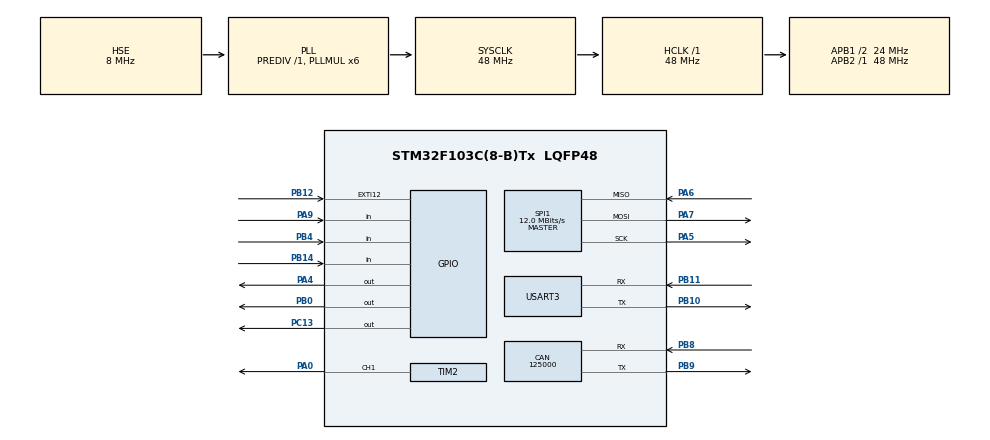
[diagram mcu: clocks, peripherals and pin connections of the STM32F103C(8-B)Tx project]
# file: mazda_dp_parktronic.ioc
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CAN.BS1=CAN_BS1_9TQ
CAN.BS2=CAN_BS2_2TQ
CAN.CalculateBaudRate=125000
CAN.CalculateTimeBit=7999.99
CAN.CalculateTimeQuantum=666.6666666666666
Mcu.Family=STM32F1
Mcu.Name=STM32F103C(8-B)Tx
Mcu.Package=LQFP48
NVIC.EXTI15_10_IRQn=true\:0\:0\:false\:false\:true\:true\:true
NVIC.PriorityGroup=NVIC_PRIORITYGROUP_4
PA0-WKUP.Signal=S_TIM2_CH1_ETR
PA13.Mode=Serial_Wire
PA13.Signal=SYS_JTMS-SWDIO
PA14.Mode=Serial_Wire
PA14.Signal=SYS_JTCK-SWCLK
PA4.Signal=GPIO_Output
PA5.Mode=Full_Duplex_Master
PA5.Signal=SPI1_SCK
PA6.Mode=Full_Duplex_Master
PA6.Signal=SPI1_MISO
PA7.Mode=Full_Duplex_Master
PA7.Signal=SPI1_MOSI
PA9.Signal=GPIO_Input
PB0.Signal=GPIO_Output
PB10.Mode=Asynchronous
PB10.Signal=USART3_TX
PB11.Mode=Asynchronous
PB11.Signal=USART3_RX
PB12.GPIO_ModeDefaultEXTI=GPIO_MODE_IT_RISING_FALLING
PB12.Signal=GPXTI12
PB14.Signal=GPIO_Input
PB4.Signal=GPIO_Input
PB8.Mode=CAN_Activate
PB8.Signal=CAN_RX
PB9.Mode=CAN_Activate
PB9.Signal=CAN_TX
PC13-TAMPER-RTC.Signal=GPIO_Output
PD0-OSC_IN.Mode=HSE-External-Oscillator
PD0-OSC_IN.Signal=RCC_OSC_IN
PD1-OSC_OUT.Mode=HSE-External-Oscillator
PD1-OSC_OUT.Signal=RCC_OSC_OUT
ProjectManager.HeapSize=0x200
ProjectManager.StackSize=0x400
ProjectManager.TargetToolchain=Makefile
RCC.AHBFreq_Value=48000000
RCC.APB1CLKDivider=RCC_HCLK_DIV2
RCC.APB1Freq_Value=24000000
RCC.APB1TimFreq_Value=48000000
RCC.APB2Freq_Value=48000000
RCC.APB2TimFreq_Value=48000000
RCC.HCLKFreq_Value=48000000
RCC.PLLMUL=RCC_PLL_MUL6
RCC.PLLSourceVirtual=RCC_PLLSOURCE_HSE
RCC.SYSCLKFreq_VALUE=48000000
RCC.SYSCLKSource=RCC_SYSCLKSOURCE_PLLCLK
RCC.USBFreq_Value=48000000
SH.S_TIM2_CH1_ETR.0=TIM2_CH1,Output Compare1 CH1
SPI1.BaudRatePrescaler=SPI_BAUDRATEPRESCALER_4
SPI1.CalculateBaudRate=12.0 MBits/s
SPI1.Direction=SPI_DIRECTION_2LINES
SPI1.Mode=SPI_MODE_MASTER
SPI1.VirtualType=VM_MASTER
TIM2.Channel-Output\ Compare1\ CH1=TIM_CHANNEL_1
USART3.VirtualMode=VM_ASYNC
board=custom

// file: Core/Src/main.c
/* USER CODE BEGIN Header */
/**
  ******************************************************************************
  * @file           : main.c
  * @brief          : Main program body
  ******************************************************************************
  * @attention
  *
  * <h2><center>&copy; Copyright (c) 2021 STMicroelectronics.
  * All rights reserved.</center></h2>
  *
  * This software component is licensed by ST under BSD 3-Clause license,
  * the "License"; You may not use this file except in compliance with the
  * License. You may obtain a copy of the License at:
  *                        opensource.org/licenses/BSD-3-Clause
  *
  ******************************************************************************
  */
/* USER CODE END Header */
#include "main.h"

/* USER CODE BEGIN Includes */
#include "mdp.h"
/* USER CODE END Includes */

CAN_HandleTypeDef hcan;

SPI_HandleTypeDef hspi1;

TIM_HandleTypeDef htim2;

UART_HandleTypeDef huart3;

void SystemClock_Config(void);
static void MX_GPIO_Init(void);
static void MX_USART3_UART_Init(void);
static void MX_CAN_Init(void);
static void MX_SPI1_Init(void);
static void MX_TIM2_Init(void);

int main(void)
{

  /* MCU Configuration--------------------------------------------------------*/

  /* Reset of all peripherals, Initializes the Flash interface and the Systick. */
  HAL_Init();

  /* Configure the system clock */
  SystemClock_Config();

  /* Initialize all configured peripherals */
  MX_GPIO_Init();
  MX_USART3_UART_Init();
  MX_CAN_Init();
  MX_SPI1_Init();
  MX_TIM2_Init();
  /* USER CODE BEGIN 2 */
  mdp_init();
  /* USER CODE END 2 */

  /* Infinite loop */
  while (1)
  {

    /* USER CODE BEGIN 3 */
    mdp_run();
  }
  /* USER CODE END 3 */
}

void SystemClock_Config(void)
{
  RCC_OscInitTypeDef RCC_OscInitStruct = {0};
  RCC_ClkInitTypeDef RCC_ClkInitStruct = {0};

  /** Initializes the RCC Oscillators according to the specified parameters
  * in the RCC_OscInitTypeDef structure.
  */
  RCC_OscInitStruct.OscillatorType = RCC_OSCILLATORTYPE_HSE;
  RCC_OscInitStruct.HSEState = RCC_HSE_ON;
  RCC_OscInitStruct.HSEPredivValue = RCC_HSE_PREDIV_DIV1;
  RCC_OscInitStruct.HSIState = RCC_HSI_ON;
  RCC_OscInitStruct.PLL.PLLState = RCC_PLL_ON;
  RCC_OscInitStruct.PLL.PLLSource = RCC_PLLSOURCE_HSE;
  RCC_OscInitStruct.PLL.PLLMUL = RCC_PLL_MUL6;
  if (HAL_RCC_OscConfig(&RCC_OscInitStruct) != HAL_OK)
  {
    Error_Handler();
  }
  /** Initializes the CPU, AHB and APB buses clocks
  */
  RCC_ClkInitStruct.ClockType = RCC_CLOCKTYPE_HCLK|RCC_CLOCKTYPE_SYSCLK
                              |RCC_CLOCKTYPE_PCLK1|RCC_CLOCKTYPE_PCLK2;
  RCC_ClkInitStruct.SYSCLKSource = RCC_SYSCLKSOURCE_PLLCLK;
  RCC_ClkInitStruct.AHBCLKDivider = RCC_SYSCLK_DIV1;
  RCC_ClkInitStruct.APB1CLKDivider = RCC_HCLK_DIV2;
  RCC_ClkInitStruct.APB2CLKDivider = RCC_HCLK_DIV1;

  if (HAL_RCC_ClockConfig(&RCC_ClkInitStruct, FLASH_LATENCY_1) != HAL_OK)
  {
    Error_Handler();
  }
}

static void MX_CAN_Init(void)
{

  hcan.Instance = CAN1;
  hcan.Init.Prescaler = 16;
  hcan.Init.Mode = CAN_MODE_NORMAL;
  hcan.Init.SyncJumpWidth = CAN_SJW_1TQ;
  hcan.Init.TimeSeg1 = CAN_BS1_9TQ;
  hcan.Init.TimeSeg2 = CAN_BS2_2TQ;
  hcan.Init.TimeTriggeredMode = DISABLE;
  hcan.Init.AutoBusOff = DISABLE;
  hcan.Init.AutoWakeUp = DISABLE;
  hcan.Init.AutoRetransmission = DISABLE;
  hcan.Init.ReceiveFifoLocked = DISABLE;
  hcan.Init.TransmitFifoPriority = DISABLE;
  if (HAL_CAN_Init(&hcan) != HAL_OK)
  {
    Error_Handler();
  }

}

static void MX_SPI1_Init(void)
{

  /* SPI1 parameter configuration*/
  hspi1.Instance = SPI1;
  hspi1.Init.Mode = SPI_MODE_MASTER;
  hspi1.Init.Direction = SPI_DIRECTION_2LINES;
  hspi1.Init.DataSize = SPI_DATASIZE_8BIT;
  hspi1.Init.CLKPolarity = SPI_POLARITY_LOW;
  hspi1.Init.CLKPhase = SPI_PHASE_1EDGE;
  hspi1.Init.NSS = SPI_NSS_SOFT;
  hspi1.Init.BaudRatePrescaler = SPI_BAUDRATEPRESCALER_4;
  hspi1.Init.FirstBit = SPI_FIRSTBIT_MSB;
  hspi1.Init.TIMode = SPI_TIMODE_DISABLE;
  hspi1.Init.CRCCalculation = SPI_CRCCALCULATION_DISABLE;
  hspi1.Init.CRCPolynomial = 10;
  if (HAL_SPI_Init(&hspi1) != HAL_OK)
  {
    Error_Handler();
  }

}

static void MX_TIM2_Init(void)
{

  TIM_MasterConfigTypeDef sMasterConfig = {0};
  TIM_OC_InitTypeDef sConfigOC = {0};
  TIM_BreakDeadTimeConfigTypeDef sBreakDeadTimeConfig = {0};

  htim2.Instance = TIM2;
  htim2.Init.Prescaler = 0;
  htim2.Init.CounterMode = TIM_COUNTERMODE_UP;
  htim2.Init.Period = 65535;
  htim2.Init.ClockDivision = TIM_CLOCKDIVISION_DIV1;
  htim2.Init.RepetitionCounter = 0;
  htim2.Init.AutoReloadPreload = TIM_AUTORELOAD_PRELOAD_ENABLE;
  if (HAL_TIM_OC_Init(&htim2) != HAL_OK)
  {
    Error_Handler();
  }
  sMasterConfig.MasterOutputTrigger = TIM_TRGO_RESET;
  sMasterConfig.MasterSlaveMode = TIM_MASTERSLAVEMODE_DISABLE;
  if (HAL_TIMEx_MasterConfigSynchronization(&htim2, &sMasterConfig) != HAL_OK)
  {
    Error_Handler();
  }
  sConfigOC.OCMode = TIM_OCMODE_TOGGLE;
  sConfigOC.Pulse = 0;
  sConfigOC.OCPolarity = TIM_OCPOLARITY_HIGH;
  sConfigOC.OCNPolarity = TIM_OCNPOLARITY_HIGH;
  sConfigOC.OCFastMode = TIM_OCFAST_DISABLE;
  sConfigOC.OCIdleState = TIM_OCIDLESTATE_RESET;
  sConfigOC.OCNIdleState = TIM_OCNIDLESTATE_RESET;
  if (HAL_TIM_OC_ConfigChannel(&htim2, &sConfigOC, TIM_CHANNEL_1) != HAL_OK)
  {
    Error_Handler();
  }
  sBreakDeadTimeConfig.OffStateRunMode = TIM_OSSR_DISABLE;
  sBreakDeadTimeConfig.OffStateIDLEMode = TIM_OSSI_DISABLE;
  sBreakDeadTimeConfig.LockLevel = TIM_LOCKLEVEL_OFF;
  sBreakDeadTimeConfig.DeadTime = 0;
  sBreakDeadTimeConfig.BreakState = TIM_BREAK_DISABLE;
  sBreakDeadTimeConfig.BreakPolarity = TIM_BREAKPOLARITY_HIGH;
  sBreakDeadTimeConfig.AutomaticOutput = TIM_AUTOMATICOUTPUT_DISABLE;
  if (HAL_TIMEx_ConfigBreakDeadTime(&htim2, &sBreakDeadTimeConfig) != HAL_OK)
  {
    Error_Handler();
  }
  HAL_TIM_MspPostInit(&htim2);

}

static void MX_USART3_UART_Init(void)
{

  huart3.Instance = USART3;
  huart3.Init.BaudRate = MDP_DEBUG_UART_SPEED;
  huart3.Init.WordLength = UART_WORDLENGTH_8B;
  huart3.Init.StopBits = UART_STOPBITS_1;
  huart3.Init.Parity = UART_PARITY_NONE;
  huart3.Init.Mode = UART_MODE_TX_RX;
  huart3.Init.HwFlowCtl = UART_HWCONTROL_NONE;
  huart3.Init.OverSampling = UART_OVERSAMPLING_16;
  if (HAL_UART_Init(&huart3) != HAL_OK)
  {
    Error_Handler();
  }

}

static void MX_GPIO_Init(void)
{
  GPIO_InitTypeDef GPIO_InitStruct = {0};

  /* GPIO Ports Clock Enable */
  __HAL_RCC_GPIOC_CLK_ENABLE();
  __HAL_RCC_GPIOD_CLK_ENABLE();
  __HAL_RCC_GPIOA_CLK_ENABLE();
  __HAL_RCC_GPIOB_CLK_ENABLE();

  /*Configure GPIO pin Output Level */
  HAL_GPIO_WritePin(GPIOC, GPIO_PIN_13, GPIO_PIN_RESET);

  /*Configure GPIO pin Output Level */
  HAL_GPIO_WritePin(GPIOA, GPIO_PIN_4, GPIO_PIN_RESET);

  /*Configure GPIO pin Output Level */
  HAL_GPIO_WritePin(GPIOB, GPIO_PIN_0, GPIO_PIN_RESET);

  /*Configure GPIO pin : PC13 */
  GPIO_InitStruct.Pin = GPIO_PIN_13;
  GPIO_InitStruct.Mode = GPIO_MODE_OUTPUT_PP;
  GPIO_InitStruct.Pull = GPIO_NOPULL;
  GPIO_InitStruct.Speed = GPIO_SPEED_FREQ_LOW;
  HAL_GPIO_Init(GPIOC, &GPIO_InitStruct);

  /*Configure GPIO pin : PA4 */
  GPIO_InitStruct.Pin = GPIO_PIN_4;
  GPIO_InitStruct.Mode = GPIO_MODE_OUTPUT_PP;
  GPIO_InitStruct.Pull = GPIO_NOPULL;
  GPIO_InitStruct.Speed = GPIO_SPEED_FREQ_LOW;
  HAL_GPIO_Init(GPIOA, &GPIO_InitStruct);

  /*Configure GPIO pin : PB0 */
  GPIO_InitStruct.Pin = GPIO_PIN_0;
  GPIO_InitStruct.Mode = GPIO_MODE_OUTPUT_PP;
  GPIO_InitStruct.Pull = GPIO_NOPULL;
  GPIO_InitStruct.Speed = GPIO_SPEED_FREQ_LOW;
  HAL_GPIO_Init(GPIOB, &GPIO_InitStruct);

  /*Configure GPIO pin : PB12 */
  GPIO_InitStruct.Pin = GPIO_PIN_12;
  GPIO_InitStruct.Mode = GPIO_MODE_IT_RISING_FALLING;
  GPIO_InitStruct.Pull = GPIO_NOPULL;
  HAL_GPIO_Init(GPIOB, &GPIO_InitStruct);

  /*Configure GPIO pins : PB14 PB4 */
  GPIO_InitStruct.Pin = GPIO_PIN_14|GPIO_PIN_4;
  GPIO_InitStruct.Mode = GPIO_MODE_INPUT;
  GPIO_InitStruct.Pull = GPIO_NOPULL;
  HAL_GPIO_Init(GPIOB, &GPIO_InitStruct);

  /*Configure GPIO pin : PA9 */
  GPIO_InitStruct.Pin = GPIO_PIN_9;
  GPIO_InitStruct.Mode = GPIO_MODE_INPUT;
  GPIO_InitStruct.Pull = GPIO_NOPULL;
  HAL_GPIO_Init(GPIOA, &GPIO_InitStruct);

  /* EXTI interrupt init*/
  HAL_NVIC_SetPriority(EXTI15_10_IRQn, 0, 0);
  HAL_NVIC_EnableIRQ(EXTI15_10_IRQn);

}

void Error_Handler(void)
{
  __disable_irq();
  while (1)
  {
  }
}

/************************ (C) COPYRIGHT STMicroelectronics *****END OF FILE****/
